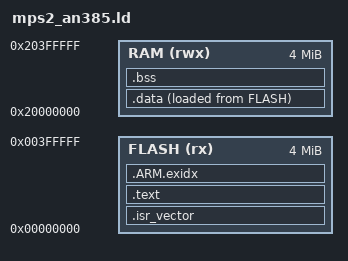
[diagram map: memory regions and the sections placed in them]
/* QEMU MPS2-AN385 (Cortex-M3) memory map: 4 MiB ZBT SSRAM at 0, 4 MiB SRAM at 0x20000000. */
ENTRY(Reset_Handler)

MEMORY
{
    FLASH (rx)  : ORIGIN = 0x00000000, LENGTH = 4M
    RAM   (rwx) : ORIGIN = 0x20000000, LENGTH = 4M
}

_estack = ORIGIN(RAM) + LENGTH(RAM);

SECTIONS
{
    .isr_vector : {
        KEEP(*(.isr_vector))
    } > FLASH

    .text : {
        *(.text .text.*)
        *(.rodata .rodata.*)
        *(.glue_7) *(.glue_7t) *(.vfp11_veneer) *(.v4_bx)
    } > FLASH

    .ARM.exidx : {
        __exidx_start = .;
        *(.ARM.exidx*)
        __exidx_end = .;
    } > FLASH

    _sidata = LOADADDR(.data);
    .data : {
        _sdata = .;
        *(.data .data.*)
        _edata = .;
    } > RAM AT > FLASH

    .bss : {
        _sbss = .;
        *(.bss .bss.*)
        *(COMMON)
        _ebss = .;
    } > RAM

    /* newlib's _sbrk grows the heap from `end`. */
    end = .;
    _end = .;
}
